# S32K148 register map
Vendor: NXP; Series: S32K; File version: 1.6
CPU: CM4 r0p1, little endian, MPU, FPU, 4 interrupt priority bits
Registers are 32-bit, read-write, reset 0x0 unless marked. A register's access mark holds for its fields unless they carry their own. Offsets are from the block's base; [hi:lo] are bit positions; {n}, {i} and the like mark numbered series.

## PDB0 — Programmable Delay Block
Base 0x40036000; register names take the prefix PDB0_
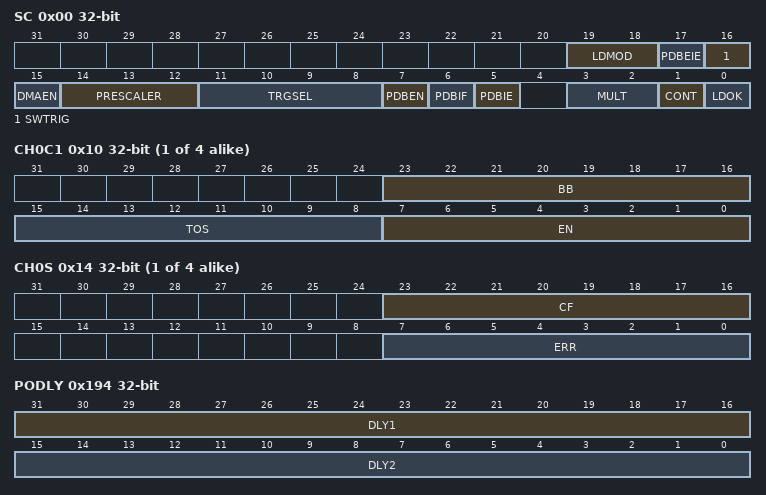
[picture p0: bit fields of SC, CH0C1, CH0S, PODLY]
0x00 SC — Status and Control register
  [19:18] LDMOD — Load Mode Select
    0=The internal registers are loaded with the values from their buffers, immediately after 1 is written to LDOK; 1=The internal registers are loaded with the values from their buffers when the PDB counter (CNT) = MOD + 1 CNT delay elapsed, after 1 is written to LDOK; 2=The internal registers are loaded with the values from their buffers when a trigger input event is detected, after 1 is written to LDOK; 3=The internal registers are loaded with the values from their buffers when either the PDB counter (CNT) = MOD + 1 CNT delay elapsed, or a trigger input event is detected, after 1 is written to LDOK
  [17] PDBEIE — PDB Sequence Error Interrupt Enable
    0=PDB sequence error interrupt disabled; 1=PDB sequence error interrupt enabled
  [16] SWTRIG wo — Software Trigger
  [15] DMAEN — DMA Enable
    0=DMA disabled; 1=DMA enabled
  [14:12] PRESCALER — Prescaler Divider Select
    0=Counting uses the peripheral clock divided by MULT (the multiplication factor); 1=Counting uses the peripheral clock divided by 2 x MULT (the multiplication factor); 2=Counting uses the peripheral clock divided by 4 x MULT (the multiplication factor); 3=Counting uses the peripheral clock divided by 8 x MULT (the multiplication factor); 4=Counting uses the peripheral clock divided by 16 x MULT (the multiplication factor); 5=Counting uses the peripheral clock divided by 32 x MULT (the multiplication factor); 6=Counting uses the peripheral clock divided by 64 x MULT (the multiplication factor); 7=Counting uses the peripheral clock divided by 128 x MULT (the multiplication factor)
  [11:8] TRGSEL — Trigger Input Source Select
    {v}=Trigger-In {v} is selected (v=0..14); 15=Software trigger is selected
  [7] PDBEN — PDB Enable
    0=PDB disabled. Counter is off.; 1=PDB enabled
  [6] PDBIF — PDB Interrupt Flag
  [5] PDBIE — PDB Interrupt Enable
    0=PDB interrupt disabled; 1=PDB interrupt enabled
  [3:2] MULT — Multiplication Factor Select for Prescaler
    0=Multiplication factor is 1; 1=Multiplication factor is 10; 2=Multiplication factor is 20; 3=Multiplication factor is 40
  [1] CONT — Continuous Mode Enable
    0=PDB operation in One-Shot mode; 1=PDB operation in Continuous mode
  [0] LDOK — Load OK
0x04 MOD reset 0xFFFF — Modulus register
  [15:0] MOD — PDB Modulus
0x08 CNT ro — Counter register
  [15:0] CNT — PDB Counter
0x0C IDLY reset 0xFFFF — Interrupt Delay register
  [15:0] IDLY — PDB Interrupt Delay
{0x10+0x28*i} CH{i}C1 (i=0..3) — Channel n Control register 1
  [23:16] BB — PDB Channel Pre-Trigger Back-to-Back Operation Enable
    0=PDB channel's corresponding pre-trigger back-to-back operation disabled; 1=PDB channel's corresponding pre-trigger back-to-back operation enabled
  [15:8] TOS — PDB Channel Pre-Trigger Output Select
    0=PDB channel's corresponding pre-trigger is in bypassed mode. The pre-trigger asserts one peripheral clock cycle after a rising edge is detected on selected trigger input source or software trigger is selected and SWTRIG is written with 1.; 1=PDB channel's corresponding pre-trigger asserts when the counter reaches the channel delay register plus one peripheral clock cycle after a rising edge is detected on selected trigger input source or software trigger is selected and SWTRIG is written with 1
  [7:0] EN — PDB Channel Pre-Trigger Enable
    0=PDB channel's corresponding pre-trigger disabled; 1=PDB channel's corresponding pre-trigger enabled
{0x14+0x28*i} CH{i}S (i=0..3) — Channel n Status register
  [23:16] CF — PDB Channel Flags
  [7:0] ERR — PDB Channel Sequence Error Flags
    0=Sequence error not detected on PDB channel's corresponding pre-trigger; 1=Sequence error detected on PDB channel's corresponding pre-trigger. ADCn block can be triggered for a conversion by one pre-trigger from PDB channel n. When one conversion, which is triggered by one of the pre-triggers from PDB channel n, is in progress, new trigger from PDB channel's corresponding pre-trigger m cannot be accepted by ADCn, and ERR[m] is set. Writing 0's to clear the sequence error flags.
{0x18+0x28*i} CH{i}DLY0 (i=0..3) — Channel n Delay 0 register
  [15:0] DLY — PDB Channel Delay
{0x1C+0x28*i} CH{i}DLY1 (i=0..3) — Channel n Delay 1 register
  [15:0] DLY — PDB Channel Delay
{0x20+0x28*i} CH{i}DLY2 (i=0..3) — Channel n Delay 2 register
  [15:0] DLY — PDB Channel Delay
{0x24+0x28*i} CH{i}DLY3 (i=0..3) — Channel n Delay 3 register
  [15:0] DLY — PDB Channel Delay
{0x28+0x28*i} CH{i}DLY4 (i=0..3) — Channel n Delay 4 register
  [15:0] DLY — PDB Channel Delay
{0x2C+0x28*i} CH{i}DLY5 (i=0..3) — Channel n Delay 5 register
  [15:0] DLY — PDB Channel Delay
{0x30+0x28*i} CH{i}DLY6 (i=0..3) — Channel n Delay 6 register
  [15:0] DLY — PDB Channel Delay
{0x34+0x28*i} CH{i}DLY7 (i=0..3) — Channel n Delay 7 register
  [15:0] DLY — PDB Channel Delay
0x190 POEN — Pulse-Out n Enable register
  [7:0] POEN — PDB Pulse-Out Enable
    0=PDB Pulse-Out disabled; 1=PDB Pulse-Out enabled
0x194 PODLY (PDB0 view) — Pulse-Out n Delay register
  [31:16] DLY1 — PDB Pulse-Out Delay 1
  [15:0] DLY2 — PDB Pulse-Out Delay 2
0x194 DLY2 16-bit reset not defined (PDB0 view) — PDB0_DLY2 register.
0x196 DLY1 16-bit reset 0xFFFF — PDB0_DLY1 register.

## PDB1 — Programmable Delay Block
Base 0x40031000; register names take the prefix PDB1_
Registers as PDB0 (with PDB0 read as PDB1).
